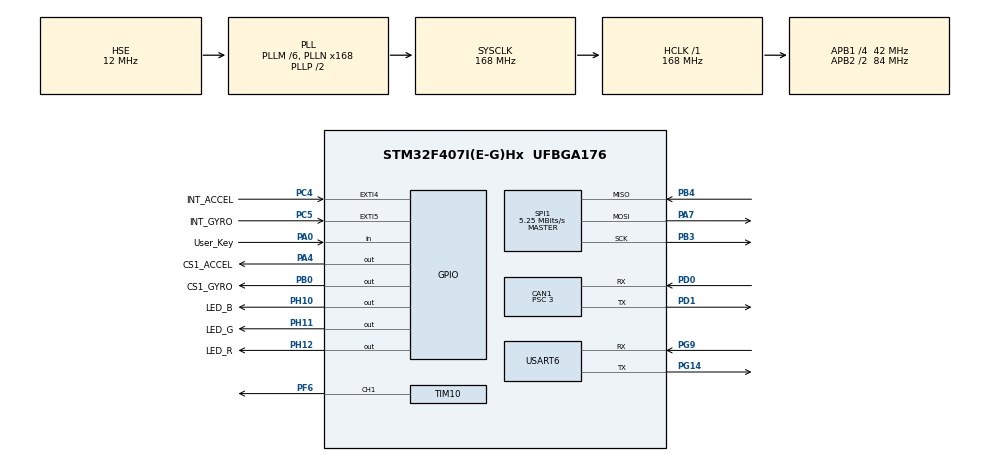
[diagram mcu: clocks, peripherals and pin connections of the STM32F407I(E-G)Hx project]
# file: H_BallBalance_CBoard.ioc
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CAN1.BS1=CAN_BS1_7TQ
CAN1.BS2=CAN_BS2_6TQ
CAN1.AutoBusOff=ENABLE
CAN1.AutoRetransmission=ENABLE
CAN1.CalculateBaudRate=1000000
CAN1.CalculateTimeBit=1000
CAN1.CalculateTimeQuantum=71.42857142857143
CAN1.Prescaler=3
CAN1.SJW=CAN_SJW_2TQ
Dma.Request0=USART6_RX
Dma.Request1=SPI1_RX
Dma.Request2=SPI1_TX
Dma.SPI1_RX.1.Direction=DMA_PERIPH_TO_MEMORY
Dma.SPI1_RX.1.FIFOMode=DMA_FIFOMODE_DISABLE
Dma.SPI1_RX.1.Instance=DMA2_Stream0
Dma.SPI1_RX.1.MemDataAlignment=DMA_MDATAALIGN_BYTE
Dma.SPI1_RX.1.MemInc=DMA_MINC_ENABLE
Dma.SPI1_RX.1.Mode=DMA_NORMAL
Dma.SPI1_RX.1.PeriphDataAlignment=DMA_PDATAALIGN_BYTE
Dma.SPI1_RX.1.PeriphInc=DMA_PINC_DISABLE
Dma.SPI1_RX.1.Priority=DMA_PRIORITY_HIGH
Dma.SPI1_TX.2.Direction=DMA_MEMORY_TO_PERIPH
Dma.SPI1_TX.2.FIFOMode=DMA_FIFOMODE_DISABLE
Dma.SPI1_TX.2.Instance=DMA2_Stream3
Dma.SPI1_TX.2.MemDataAlignment=DMA_MDATAALIGN_BYTE
Dma.SPI1_TX.2.MemInc=DMA_MINC_ENABLE
Dma.SPI1_TX.2.Mode=DMA_NORMAL
Dma.SPI1_TX.2.PeriphDataAlignment=DMA_PDATAALIGN_BYTE
Dma.SPI1_TX.2.PeriphInc=DMA_PINC_DISABLE
Dma.SPI1_TX.2.Priority=DMA_PRIORITY_HIGH
Dma.USART6_RX.0.Direction=DMA_PERIPH_TO_MEMORY
Dma.USART6_RX.0.FIFOMode=DMA_FIFOMODE_DISABLE
Dma.USART6_RX.0.Instance=DMA2_Stream1
Dma.USART6_RX.0.MemDataAlignment=DMA_MDATAALIGN_BYTE
Dma.USART6_RX.0.MemInc=DMA_MINC_ENABLE
Dma.USART6_RX.0.Mode=DMA_NORMAL
Dma.USART6_RX.0.PeriphDataAlignment=DMA_PDATAALIGN_BYTE
Dma.USART6_RX.0.PeriphInc=DMA_PINC_DISABLE
Dma.USART6_RX.0.Priority=DMA_PRIORITY_MEDIUM
FREERTOS.Tasks01=BallControlTask,40,512,BallControlTask_Entry,As external,NULL,Dynamic,NULL,NULL;ImuAccelTask,8,512,ImuAccelTask_Entry,As external,NULL,Dynamic,NULL,NULL;VisionCommTask,24,768,VisionCommTask_Entry,As external,NULL,Dynamic,NULL,NULL
FREERTOS.configENABLE_FPU=1
Mcu.Family=STM32F4
Mcu.Name=STM32F407I(E-G)Hx
Mcu.Package=UFBGA176
NVIC.CAN1_RX0_IRQn=true\:5\:0\:true\:false\:true\:true\:true\:true\:true
NVIC.CAN1_RX1_IRQn=true\:5\:0\:false\:false\:true\:true\:true\:true\:true
NVIC.CAN1_SCE_IRQn=true\:5\:0\:false\:false\:true\:true\:true\:true\:true
NVIC.CAN1_TX_IRQn=true\:6\:0\:true\:false\:true\:true\:true\:true\:true
NVIC.DMA2_Stream0_IRQn=true\:5\:0\:false\:false\:true\:true\:false\:true\:true
NVIC.DMA2_Stream1_IRQn=true\:5\:0\:false\:false\:true\:true\:false\:true\:true
NVIC.DMA2_Stream3_IRQn=true\:5\:0\:false\:false\:true\:true\:false\:true\:true
NVIC.EXTI4_IRQn=true\:5\:0\:true\:false\:true\:true\:true\:true\:true
NVIC.EXTI9_5_IRQn=true\:5\:0\:true\:false\:true\:true\:true\:true\:true
NVIC.PriorityGroup=NVIC_PRIORITYGROUP_4
NVIC.SPI1_IRQn=true\:5\:0\:true\:false\:true\:true\:true\:true\:true
NVIC.TIM8_TRG_COM_TIM14_IRQn=true\:7\:0\:true\:false\:true\:true\:true\:true\:true
NVIC.USART6_IRQn=true\:6\:0\:true\:false\:true\:true\:true\:true\:true
PA0-WKUP.GPIO_Label=User_Key
PA0-WKUP.Signal=GPIO_Input
PA13.Mode=Serial_Wire
PA13.Signal=SYS_JTMS-SWDIO
PA14.Mode=Serial_Wire
PA14.Signal=SYS_JTCK-SWCLK
PA4.GPIO_Label=CS1_ACCEL
PA4.PinState=GPIO_PIN_SET
PA4.Signal=GPIO_Output
PA7.Mode=Full_Duplex_Master
PA7.Signal=SPI1_MOSI
PB0.GPIO_Label=CS1_GYRO
PB0.PinState=GPIO_PIN_SET
PB0.Signal=GPIO_Output
PB3.Mode=Full_Duplex_Master
PB3.Signal=SPI1_SCK
PB4.Mode=Full_Duplex_Master
PB4.Signal=SPI1_MISO
PC14-OSC32_IN.Mode=LSE-External-Oscillator
PC14-OSC32_IN.Signal=RCC_OSC32_IN
PC15-OSC32_OUT.Mode=LSE-External-Oscillator
PC15-OSC32_OUT.Signal=RCC_OSC32_OUT
PC4.GPIO_Label=INT_ACCEL
PC4.GPIO_ModeDefaultEXTI=GPIO_MODE_IT_FALLING
PC4.Signal=GPXTI4
PC5.GPIO_Label=INT_GYRO
PC5.GPIO_ModeDefaultEXTI=GPIO_MODE_IT_FALLING
PC5.Signal=GPXTI5
PD0.Mode=CAN_Activate
PD0.Signal=CAN1_RX
PD1.Mode=CAN_Activate
PD1.Signal=CAN1_TX
PF6.Signal=S_TIM10_CH1
PG14.Mode=Asynchronous
PG14.Signal=USART6_TX
PG9.Mode=Asynchronous
PG9.Signal=USART6_RX
PH0-OSC_IN.Mode=HSE-External-Oscillator
PH0-OSC_IN.Signal=RCC_OSC_IN
PH1-OSC_OUT.Mode=HSE-External-Oscillator
PH1-OSC_OUT.Signal=RCC_OSC_OUT
PH10.GPIO_Label=LED_B
PH10.GPIO_PuPd=GPIO_NOPULL
PH10.GPIO_Speed=GPIO_SPEED_FREQ_LOW
PH10.PinState=GPIO_PIN_RESET
PH10.Signal=GPIO_Output
PH11.GPIO_Label=LED_G
PH11.GPIO_PuPd=GPIO_NOPULL
PH11.GPIO_Speed=GPIO_SPEED_FREQ_LOW
PH11.PinState=GPIO_PIN_RESET
PH11.Signal=GPIO_Output
PH12.GPIO_Label=LED_R
PH12.GPIO_PuPd=GPIO_NOPULL
PH12.GPIO_Speed=GPIO_SPEED_FREQ_LOW
PH12.PinState=GPIO_PIN_RESET
PH12.Signal=GPIO_Output
ProjectManager.HeapSize=0x200
ProjectManager.StackSize=0x400
ProjectManager.TargetToolchain=CMake
RCC.48MHZClocksFreq_Value=84000000
RCC.AHBFreq_Value=168000000
RCC.APB1CLKDivider=RCC_HCLK_DIV4
RCC.APB1Freq_Value=42000000
RCC.APB1TimFreq_Value=84000000
RCC.APB2CLKDivider=RCC_HCLK_DIV2
RCC.APB2Freq_Value=84000000
RCC.APB2TimFreq_Value=168000000
RCC.CortexFreq_Value=168000000
RCC.HCLKFreq_Value=168000000
RCC.HSE_VALUE=12000000
RCC.HSI_VALUE=16000000
RCC.PLLM=6
RCC.PLLN=168
RCC.PLLSourceVirtual=RCC_PLLSOURCE_HSE
RCC.SYSCLKFreq_VALUE=168000000
RCC.SYSCLKSource=RCC_SYSCLKSOURCE_PLLCLK
RCC.VCOOutputFreq_Value=336000000
SH.S_TIM10_CH1.0=TIM10_CH1,PWM Generation1 CH1
SPI1.BaudRatePrescaler=SPI_BAUDRATEPRESCALER_16
SPI1.CLKPhase=SPI_PHASE_2EDGE
SPI1.CLKPolarity=SPI_POLARITY_HIGH
SPI1.CalculateBaudRate=5.25 MBits/s
SPI1.Direction=SPI_DIRECTION_2LINES
SPI1.Mode=SPI_MODE_MASTER
SPI1.VirtualType=VM_MASTER
TIM10.AutoReloadPreload=TIM_AUTORELOAD_PRELOAD_ENABLE
TIM10.Channel=TIM_CHANNEL_1
TIM10.Period=2000-1
TIM10.Prescaler=84-1
TIM14.Period=1000-1
TIM14.Prescaler=420-1
USART6.VirtualMode=VM_ASYNC
VP_FREERTOS_VS_CMSIS_V2.Mode=CMSIS_V2
VP_TIM10_VS_ClockSourceINT.Mode=Enable_Timer
VP_TIM14_VS_ClockSourceINT.Mode=Enable_Timer
board=custom

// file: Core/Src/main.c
/* USER CODE BEGIN Header */
/**
  ******************************************************************************
  * @file           : main.c
  * @brief          : Main program body
  ******************************************************************************
  * @attention
  *
  * Copyright (c) 2025 STMicroelectronics.
  * All rights reserved.
  *
  * This software is licensed under terms that can be found in the LICENSE file
  * in the root directory of this software component.
  * If no LICENSE file comes with this software, it is provided AS-IS.
  *
  ******************************************************************************
  */
/* USER CODE END Header */
#include "main.h"
#include "cmsis_os.h"
#include "can.h"
#include "dma.h"
#include "spi.h"
#include "tim.h"
#include "usart.h"
#include "gpio.h"

/* USER CODE BEGIN Includes */

#ifdef HBALL_MINIMAL_UART_TEST
#include "MinimalUartTest.h"
#endif
#include "SafetyWatchdog.h"

/* USER CODE END Includes */

void SystemClock_Config(void);
void MX_FREERTOS_Init(void);

int main(void)
{

  /* MCU Configuration--------------------------------------------------------*/

  /* Reset of all peripherals, Initializes the Flash interface and the Systick. */
  HAL_Init();

  /* Configure the system clock */
  SystemClock_Config();

  /* USER CODE BEGIN SysInit */

#ifndef HBALL_MINIMAL_UART_TEST
  SafetyWatchdog_Init();
#endif

  /* USER CODE END SysInit */

  /* Initialize all configured peripherals */
#ifdef HBALL_MINIMAL_UART_TEST
  MinimalUartTest_InitGpio();
  MX_USART6_UART_Init();
  MinimalUartTest_Run();
#else
  MX_GPIO_Init();
  MX_DMA_Init();
  MX_CAN1_Init();
  MX_SPI1_Init();
  MX_TIM10_Init();
  MX_USART6_UART_Init();
  MX_TIM14_Init();
#endif

#ifndef HBALL_MINIMAL_UART_TEST
  /* Init scheduler */
  if (osKernelInitialize() != osOK)
  {
    SafetyWatchdog_Fatal(SAFETY_FATAL_KERNEL_INIT);
  }
  MX_FREERTOS_Init();

  /* Start scheduler */
  if (osKernelStart() != osOK)
  {
    SafetyWatchdog_Fatal(SAFETY_FATAL_KERNEL_START);
  }
#endif

  /* We should never get here as control is now taken by the scheduler */

  /* Infinite loop */
  while (1)
  {

  }
}

void SystemClock_Config(void)
{
  RCC_OscInitTypeDef RCC_OscInitStruct = {0};
  RCC_ClkInitTypeDef RCC_ClkInitStruct = {0};

  /** Configure the main internal regulator output voltage
  */
  __HAL_RCC_PWR_CLK_ENABLE();
  __HAL_PWR_VOLTAGESCALING_CONFIG(PWR_REGULATOR_VOLTAGE_SCALE1);

  /** Initializes the RCC Oscillators according to the specified parameters
  * in the RCC_OscInitTypeDef structure.
  */
  RCC_OscInitStruct.OscillatorType = RCC_OSCILLATORTYPE_HSE;
  RCC_OscInitStruct.HSEState = RCC_HSE_ON;
  RCC_OscInitStruct.PLL.PLLState = RCC_PLL_ON;
  RCC_OscInitStruct.PLL.PLLSource = RCC_PLLSOURCE_HSE;
  RCC_OscInitStruct.PLL.PLLM = 6;
  RCC_OscInitStruct.PLL.PLLN = 168;
  RCC_OscInitStruct.PLL.PLLP = RCC_PLLP_DIV2;
  RCC_OscInitStruct.PLL.PLLQ = 4;
  if (HAL_RCC_OscConfig(&RCC_OscInitStruct) != HAL_OK)
  {
    Error_Handler();
  }

  /** Initializes the CPU, AHB and APB buses clocks
  */
  RCC_ClkInitStruct.ClockType = RCC_CLOCKTYPE_HCLK|RCC_CLOCKTYPE_SYSCLK
                              |RCC_CLOCKTYPE_PCLK1|RCC_CLOCKTYPE_PCLK2;
  RCC_ClkInitStruct.SYSCLKSource = RCC_SYSCLKSOURCE_PLLCLK;
  RCC_ClkInitStruct.AHBCLKDivider = RCC_SYSCLK_DIV1;
  RCC_ClkInitStruct.APB1CLKDivider = RCC_HCLK_DIV4;
  RCC_ClkInitStruct.APB2CLKDivider = RCC_HCLK_DIV2;

  if (HAL_RCC_ClockConfig(&RCC_ClkInitStruct, FLASH_LATENCY_5) != HAL_OK)
  {
    Error_Handler();
  }
}

void Error_Handler(void)
{
  /* USER CODE BEGIN Error_Handler_Debug */
  /* User can add his own implementation to report the HAL error return state */
  SafetyWatchdog_Fatal(SAFETY_FATAL_ERROR_HANDLER);
  /* USER CODE END Error_Handler_Debug */
}

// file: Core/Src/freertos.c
/* USER CODE BEGIN Header */
/**
  ******************************************************************************
  * File Name          : freertos.c
  * Description        : Code for freertos applications
  ******************************************************************************
  * @attention
  *
  * Copyright (c) 2025 STMicroelectronics.
  * All rights reserved.
  *
  * This software is licensed under terms that can be found in the LICENSE file
  * in the root directory of this software component.
  * If no LICENSE file comes with this software, it is provided AS-IS.
  *
  ******************************************************************************
  */
/* USER CODE END Header */

#include "FreeRTOS.h"
#include "task.h"
#include "main.h"
#include "cmsis_os.h"

/* USER CODE BEGIN Includes */
#include "task_public.h"
#include "SafetyWatchdog.h"
/* USER CODE END Includes */

/* Definitions for BallControlTask */
osThreadId_t BallControlTaskHandle;
const osThreadAttr_t BallControlTask_attributes = {
  .name = "BallControlTask",
  .stack_size = 512 * 4,
  .priority = (osPriority_t) osPriorityHigh,
};
/* Definitions for ImuAccelTask */
osThreadId_t ImuAccelTaskHandle;
const osThreadAttr_t ImuAccelTask_attributes = {
  .name = "ImuAccelTask",
  .stack_size = 512 * 4,
  .priority = (osPriority_t) osPriorityLow,
};
/* Definitions for VisionCommTask */
osThreadId_t VisionCommTaskHandle;
const osThreadAttr_t VisionCommTask_attributes = {
  .name = "VisionCommTask",
  .stack_size = 768 * 4,
  .priority = (osPriority_t) osPriorityNormal,
};

void MX_FREERTOS_Init(void); /* (MISRA C 2004 rule 8.1) */

void MX_FREERTOS_Init(void) {

  /* Create the thread(s) */
  /* creation of BallControlTask */
  BallControlTaskHandle = osThreadNew(BallControlTask_Entry, NULL, &BallControlTask_attributes);
  if (BallControlTaskHandle == NULL)
  {
    HAL_GPIO_WritePin(LED_B_GPIO_Port, LED_B_Pin, GPIO_PIN_RESET);
    HAL_GPIO_WritePin(LED_G_GPIO_Port, LED_G_Pin, GPIO_PIN_RESET);
    HAL_GPIO_WritePin(LED_R_GPIO_Port, LED_R_Pin, GPIO_PIN_SET);
    Error_Handler();
  }

  /* creation of ImuAccelTask */
  ImuAccelTaskHandle = osThreadNew(ImuAccelTask_Entry, NULL, &ImuAccelTask_attributes);
  if (ImuAccelTaskHandle == NULL)
  {
    HAL_GPIO_WritePin(LED_B_GPIO_Port, LED_B_Pin, GPIO_PIN_RESET);
    HAL_GPIO_WritePin(LED_G_GPIO_Port, LED_G_Pin, GPIO_PIN_RESET);
    HAL_GPIO_WritePin(LED_R_GPIO_Port, LED_R_Pin, GPIO_PIN_SET);
    Error_Handler();
  }

  /* creation of VisionCommTask */
  VisionCommTaskHandle = osThreadNew(VisionCommTask_Entry, NULL, &VisionCommTask_attributes);
  if (VisionCommTaskHandle == NULL)
  {
    HAL_GPIO_WritePin(LED_B_GPIO_Port, LED_B_Pin, GPIO_PIN_RESET);
    HAL_GPIO_WritePin(LED_G_GPIO_Port, LED_G_Pin, GPIO_PIN_RESET);
    HAL_GPIO_WritePin(LED_R_GPIO_Port, LED_R_Pin, GPIO_PIN_SET);
    Error_Handler();
  }

}

/* USER CODE BEGIN Application */

void vApplicationMallocFailedHook(void)
{
  SafetyWatchdog_Fatal(SAFETY_FATAL_MALLOC);
}

void vApplicationStackOverflowHook(TaskHandle_t task, char *taskName)
{
  (void)task;
  (void)taskName;
  SafetyWatchdog_Fatal(SAFETY_FATAL_STACK_OVERFLOW);
}

/* USER CODE END Application */
